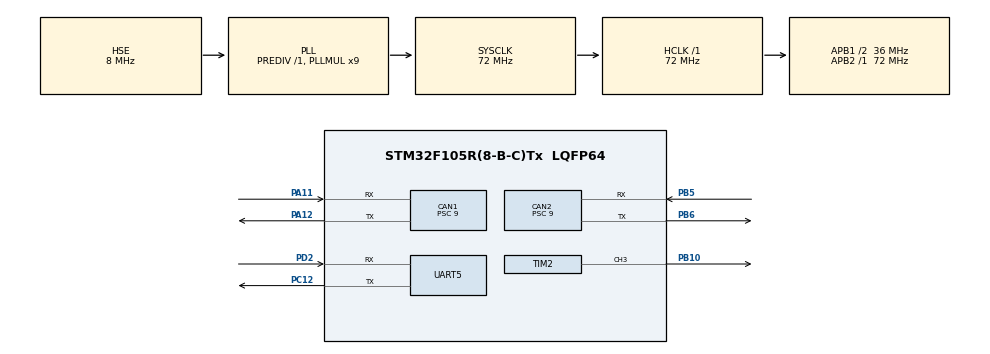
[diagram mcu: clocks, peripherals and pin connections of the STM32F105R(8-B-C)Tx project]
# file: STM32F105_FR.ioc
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CAN1.BS1=CAN_BS1_2TQ
CAN1.CalculateBaudRate=1000000
CAN1.CalculateTimeBit=1000
CAN1.CalculateTimeQuantum=250.0
CAN1.NART=ENABLE
CAN1.Prescaler=9
CAN2.BS1=CAN_BS1_2TQ
CAN2.CalculateBaudRate=1000000
CAN2.CalculateTimeBit=1000
CAN2.CalculateTimeQuantum=250.0
CAN2.NART=ENABLE
CAN2.Prescaler=9
Dma.Request0=TIM2_CH3
Dma.TIM2_CH3.0.Direction=DMA_MEMORY_TO_PERIPH
Dma.TIM2_CH3.0.Instance=DMA1_Channel1
Dma.TIM2_CH3.0.MemDataAlignment=DMA_MDATAALIGN_HALFWORD
Dma.TIM2_CH3.0.MemInc=DMA_MINC_ENABLE
Dma.TIM2_CH3.0.Mode=DMA_NORMAL
Dma.TIM2_CH3.0.PeriphDataAlignment=DMA_PDATAALIGN_HALFWORD
Dma.TIM2_CH3.0.PeriphInc=DMA_PINC_DISABLE
Dma.TIM2_CH3.0.Priority=DMA_PRIORITY_HIGH
FREERTOS.Tasks01=defaultTask,8,128,StartDefaultTask,Default,NULL,Dynamic,NULL,NULL;WS2812Task,24,128,StartWS2812Task,As external,NULL,Dynamic,NULL,NULL;M3508Task,41,128,StartM3508ControlTask,As external,NULL,Dynamic,NULL,NULL;InitTask,55,256,StartInitTask,As external,NULL,Dynamic,NULL,NULL;HUB75Task,32,128,StartHUB75Task,As external,NULL,Dynamic,NULL,NULL;ErrorHandlerTask,47,128,StartErrorHandlerTask,As external,NULL,Dynamic,NULL,NULL
FREERTOS.configENABLE_FPU=1
FREERTOS.configMAX_TASK_NAME_LEN=24
FREERTOS.configTOTAL_HEAP_SIZE=8192
Mcu.Family=STM32F1
Mcu.Name=STM32F105R(8-B-C)Tx
Mcu.Package=LQFP64
NVIC.CAN1_RX0_IRQn=true\:5\:0\:false\:false\:true\:true\:true\:true\:true
NVIC.CAN1_RX1_IRQn=true\:5\:0\:false\:false\:true\:true\:true\:true\:true
NVIC.CAN2_RX0_IRQn=true\:5\:0\:false\:false\:true\:true\:true\:true\:true
NVIC.CAN2_RX1_IRQn=true\:5\:0\:false\:false\:true\:true\:true\:true\:true
NVIC.DMA1_Channel1_IRQn=true\:5\:0\:false\:false\:true\:true\:false\:true\:true
NVIC.PriorityGroup=NVIC_PRIORITYGROUP_4
NVIC.TIM3_IRQn=true\:5\:0\:false\:false\:true\:true\:true\:true\:true
NVIC.TIM7_IRQn=true\:15\:0\:false\:false\:true\:false\:false\:true\:true
NVIC.TimeBase=TIM7_IRQn
NVIC.TimeBaseIP=TIM7
NVIC.UART5_IRQn=true\:5\:0\:false\:false\:true\:true\:true\:true\:true
PA11.Mode=CAN_Activate
PA11.Signal=CAN1_RX
PA12.Mode=CAN_Activate
PA12.Signal=CAN1_TX
PA13.Mode=Serial_Wire
PA13.Signal=SYS_JTMS-SWDIO
PA14.Mode=Serial_Wire
PA14.Signal=SYS_JTCK-SWCLK
PB10.GPIO_ModeDefaultPP=GPIO_MODE_AF_OD
PB10.GPIO_Speed=GPIO_SPEED_FREQ_HIGH
PB10.Signal=S_TIM2_CH3
PB5.Mode=CAN_Activate
PB5.Signal=CAN2_RX
PB6.Mode=CAN_Activate
PB6.Signal=CAN2_TX
PC12.Mode=Asynchronous
PC12.Signal=UART5_TX
PD0-OSC_IN.Mode=HSE-External-Clock-Source
PD0-OSC_IN.Signal=RCC_OSC_IN
PD1-OSC_OUT.Mode=HSE-External-Clock-Source
PD1-OSC_OUT.Signal=RCC_OSC_OUT
PD2.Mode=Asynchronous
PD2.Signal=UART5_RX
ProjectManager.HeapSize=0x200
ProjectManager.StackSize=0x400
ProjectManager.TargetToolchain=CMake
RCC.AHBFreq_Value=72000000
RCC.APB1CLKDivider=RCC_HCLK_DIV2
RCC.APB1Freq_Value=36000000
RCC.APB1TimFreq_Value=72000000
RCC.APB2Freq_Value=72000000
RCC.APB2TimFreq_Value=72000000
RCC.HCLKFreq_Value=72000000
RCC.PLLMUL=RCC_PLL_MUL9
RCC.PLLSourceVirtual=RCC_PLLSOURCE_HSE
RCC.SYSCLKFreq_VALUE=72000000
RCC.SYSCLKSource=RCC_SYSCLKSOURCE_PLLCLK
RCC.USBFreq_Value=48000000
SH.S_TIM2_CH3.0=TIM2_CH3,PWM Generation3 CH3
TIM2.Channel-PWM\ Generation3\ CH3=TIM_CHANNEL_3
TIM2.Prescaler=0
TIM3.Period=1000-1
TIM3.Prescaler=72-1
UART5.VirtualMode=Asynchronous
VP_FREERTOS_VS_CMSIS_V2.Mode=CMSIS_V2
VP_SYS_VS_tim7.Mode=TIM7
VP_TIM2_VS_ClockSourceINT.Mode=Internal
VP_TIM3_VS_ClockSourceINT.Mode=Internal
board=custom

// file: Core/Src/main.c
/* USER CODE BEGIN Header */
/**
  ******************************************************************************
  * @file           : main.c
  * @brief          : Main program body
  ******************************************************************************
  * @attention
  *
  * Copyright (c) 2026 STMicroelectronics.
  * All rights reserved.
  *
  * This software is licensed under terms that can be found in the LICENSE file
  * in the root directory of this software component.
  * If no LICENSE file comes with this software, it is provided AS-IS.
  *
  ******************************************************************************
  */
/* USER CODE END Header */
#include "main.h"
#include "cmsis_os.h"
#include "can.h"
#include "dma.h"
#include "tim.h"
#include "usart.h"
#include "gpio.h"

/* USER CODE BEGIN Includes */
#include "timer.h"
/* USER CODE END Includes */

void SystemClock_Config(void);
void MX_FREERTOS_Init(void);

int main(void)
{

  /* MCU Configuration--------------------------------------------------------*/

  /* Reset of all peripherals, Initializes the Flash interface and the Systick. */
  HAL_Init();

  /* Configure the system clock */
  SystemClock_Config();

  /* Initialize all configured peripherals */
  MX_GPIO_Init();
  MX_DMA_Init();
  MX_CAN1_Init();
  MX_CAN2_Init();
  MX_TIM2_Init();
  MX_TIM3_Init();
  MX_UART5_Init();

  /* Init scheduler */
  osKernelInitialize();  /* Call init function for freertos objects (in cmsis_os2.c) */
  MX_FREERTOS_Init();

  /* Start scheduler */
  osKernelStart();

  /* We should never get here as control is now taken by the scheduler */

  /* Infinite loop */
  while (1)
  {

  }
}

void SystemClock_Config(void)
{
  RCC_OscInitTypeDef RCC_OscInitStruct = {0};
  RCC_ClkInitTypeDef RCC_ClkInitStruct = {0};

  /** Initializes the RCC Oscillators according to the specified parameters
  * in the RCC_OscInitTypeDef structure.
  */
  RCC_OscInitStruct.OscillatorType = RCC_OSCILLATORTYPE_HSE;
  RCC_OscInitStruct.HSEState = RCC_HSE_BYPASS;
  RCC_OscInitStruct.HSEPredivValue = RCC_HSE_PREDIV_DIV1;
  RCC_OscInitStruct.HSIState = RCC_HSI_ON;
  RCC_OscInitStruct.Prediv1Source = RCC_PREDIV1_SOURCE_HSE;
  RCC_OscInitStruct.PLL.PLLState = RCC_PLL_ON;
  RCC_OscInitStruct.PLL.PLLSource = RCC_PLLSOURCE_HSE;
  RCC_OscInitStruct.PLL.PLLMUL = RCC_PLL_MUL9;
  RCC_OscInitStruct.PLL2.PLL2State = RCC_PLL_NONE;
  if (HAL_RCC_OscConfig(&RCC_OscInitStruct) != HAL_OK)
  {
    Error_Handler();
  }

  /** Initializes the CPU, AHB and APB buses clocks
  */
  RCC_ClkInitStruct.ClockType = RCC_CLOCKTYPE_HCLK|RCC_CLOCKTYPE_SYSCLK
                              |RCC_CLOCKTYPE_PCLK1|RCC_CLOCKTYPE_PCLK2;
  RCC_ClkInitStruct.SYSCLKSource = RCC_SYSCLKSOURCE_PLLCLK;
  RCC_ClkInitStruct.AHBCLKDivider = RCC_SYSCLK_DIV1;
  RCC_ClkInitStruct.APB1CLKDivider = RCC_HCLK_DIV2;
  RCC_ClkInitStruct.APB2CLKDivider = RCC_HCLK_DIV1;

  if (HAL_RCC_ClockConfig(&RCC_ClkInitStruct, FLASH_LATENCY_2) != HAL_OK)
  {
    Error_Handler();
  }

  /** Configure the Systick interrupt time
  */
  __HAL_RCC_PLLI2S_ENABLE();
}

void HAL_TIM_PeriodElapsedCallback(TIM_HandleTypeDef *htim)
{
  if (htim->Instance == TIM7)
  {
    HAL_IncTick();
  }
  /* USER CODE BEGIN Callback 1 */
  TIM_Callback(htim);
  /* USER CODE END Callback 1 */
}

void Error_Handler(void)
{
  __disable_irq();
  while (1)
  {
  }
}

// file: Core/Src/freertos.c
/* USER CODE BEGIN Header */
/**
  ******************************************************************************
  * File Name          : freertos.c
  * Description        : Code for freertos applications
  ******************************************************************************
  * @attention
  *
  * Copyright (c) 2026 STMicroelectronics.
  * All rights reserved.
  *
  * This software is licensed under terms that can be found in the LICENSE file
  * in the root directory of this software component.
  * If no LICENSE file comes with this software, it is provided AS-IS.
  *
  ******************************************************************************
  */
/* USER CODE END Header */

#include "FreeRTOS.h"
#include "task.h"
#include "main.h"
#include "cmsis_os.h"

/* USER CODE BEGIN Includes */
#include "HUB75Task.h"
/* USER CODE END Includes */

/* Definitions for defaultTask */
osThreadId_t defaultTaskHandle;
const osThreadAttr_t defaultTask_attributes = {
  .name = "defaultTask",
  .stack_size = 128 * 4,
  .priority = (osPriority_t) osPriorityLow,
};
/* Definitions for WS2812Task */
osThreadId_t WS2812TaskHandle;
const osThreadAttr_t WS2812Task_attributes = {
  .name = "WS2812Task",
  .stack_size = 128 * 4,
  .priority = (osPriority_t) osPriorityNormal,
};
/* Definitions for M3508Task */
osThreadId_t M3508TaskHandle;
const osThreadAttr_t M3508Task_attributes = {
  .name = "M3508Task",
  .stack_size = 128 * 4,
  .priority = (osPriority_t) osPriorityHigh1,
};
/* Definitions for InitTask */
osThreadId_t InitTaskHandle;
const osThreadAttr_t InitTask_attributes = {
  .name = "InitTask",
  .stack_size = 256 * 4,
  .priority = (osPriority_t) osPriorityRealtime7,
};
/* Definitions for HUB75Task */
osThreadId_t HUB75TaskHandle;
const osThreadAttr_t HUB75Task_attributes = {
  .name = "HUB75Task",
  .stack_size = 128 * 4,
  .priority = (osPriority_t) osPriorityAboveNormal,
};
/* Definitions for ErrorHandlerTask */
osThreadId_t ErrorHandlerTaskHandle;
const osThreadAttr_t ErrorHandlerTask_attributes = {
  .name = "ErrorHandlerTask",
  .stack_size = 128 * 4,
  .priority = (osPriority_t) osPriorityHigh7,
};

void StartDefaultTask(void *argument);
extern void StartWS2812Task(void *argument);
extern void StartM3508ControlTask(void *argument);
extern void StartInitTask(void *argument);
extern void StartHUB75Task(void *argument);
extern void StartErrorHandlerTask(void *argument);

void MX_FREERTOS_Init(void); /* (MISRA C 2004 rule 8.1) */

void MX_FREERTOS_Init(void) {

  /* Create the thread(s) */
  /* creation of defaultTask */
  defaultTaskHandle = osThreadNew(StartDefaultTask, NULL, &defaultTask_attributes);

  /* creation of WS2812Task */
  WS2812TaskHandle = osThreadNew(StartWS2812Task, NULL, &WS2812Task_attributes);

  /* creation of M3508Task */
  M3508TaskHandle = osThreadNew(StartM3508ControlTask, NULL, &M3508Task_attributes);

  /* creation of InitTask */
  InitTaskHandle = osThreadNew(StartInitTask, NULL, &InitTask_attributes);

  /* creation of HUB75Task */
  HUB75TaskHandle = osThreadNew(StartHUB75Task, NULL, &HUB75Task_attributes);

  /* creation of ErrorHandlerTask */
  ErrorHandlerTaskHandle = osThreadNew(StartErrorHandlerTask, NULL, &ErrorHandlerTask_attributes);

}

void StartDefaultTask(void *argument)
{
  for(;;)
  {
    osDelay(1);
  }
}
